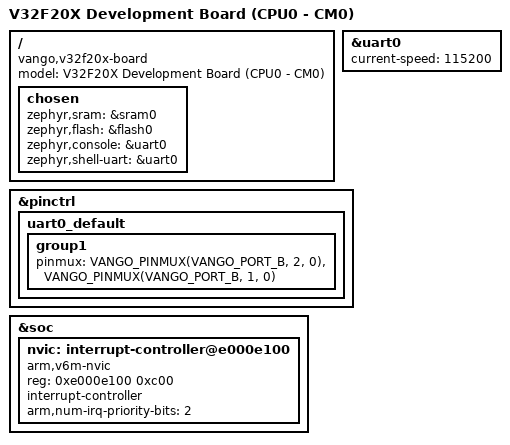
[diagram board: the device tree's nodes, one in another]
/dts-v1/;
#include <arm/vango/v32f20x/v32f20x.dtsi>

/ {
    model = "V32F20X Development Board (CPU0 - CM0)";
    compatible = "vango,v32f20x-board";

    chosen {
        zephyr,sram = &sram0;
        zephyr,flash = &flash0;
        zephyr,console = &uart0;
        zephyr,shell-uart = &uart0;
    };
};

&uart0 {
    status = "okay";
    current-speed = <115200>;
};

&pinctrl {
    uart0_default: uart0_default {
        group1 {
            pinmux = <VANGO_PINMUX(VANGO_PORT_B, 2, 0)>, /* UART0_TX */
                     <VANGO_PINMUX(VANGO_PORT_B, 1, 0)>; /* UART0_RX */
        };
    };
};

&soc {
    nvic: interrupt-controller@e000e100 {
        compatible = "arm,v6m-nvic";
        reg = <0xe000e100 0xc00>;
        interrupt-controller;
        #interrupt-cells = <2>;
        arm,num-irq-priority-bits = <2>;
    };
};
